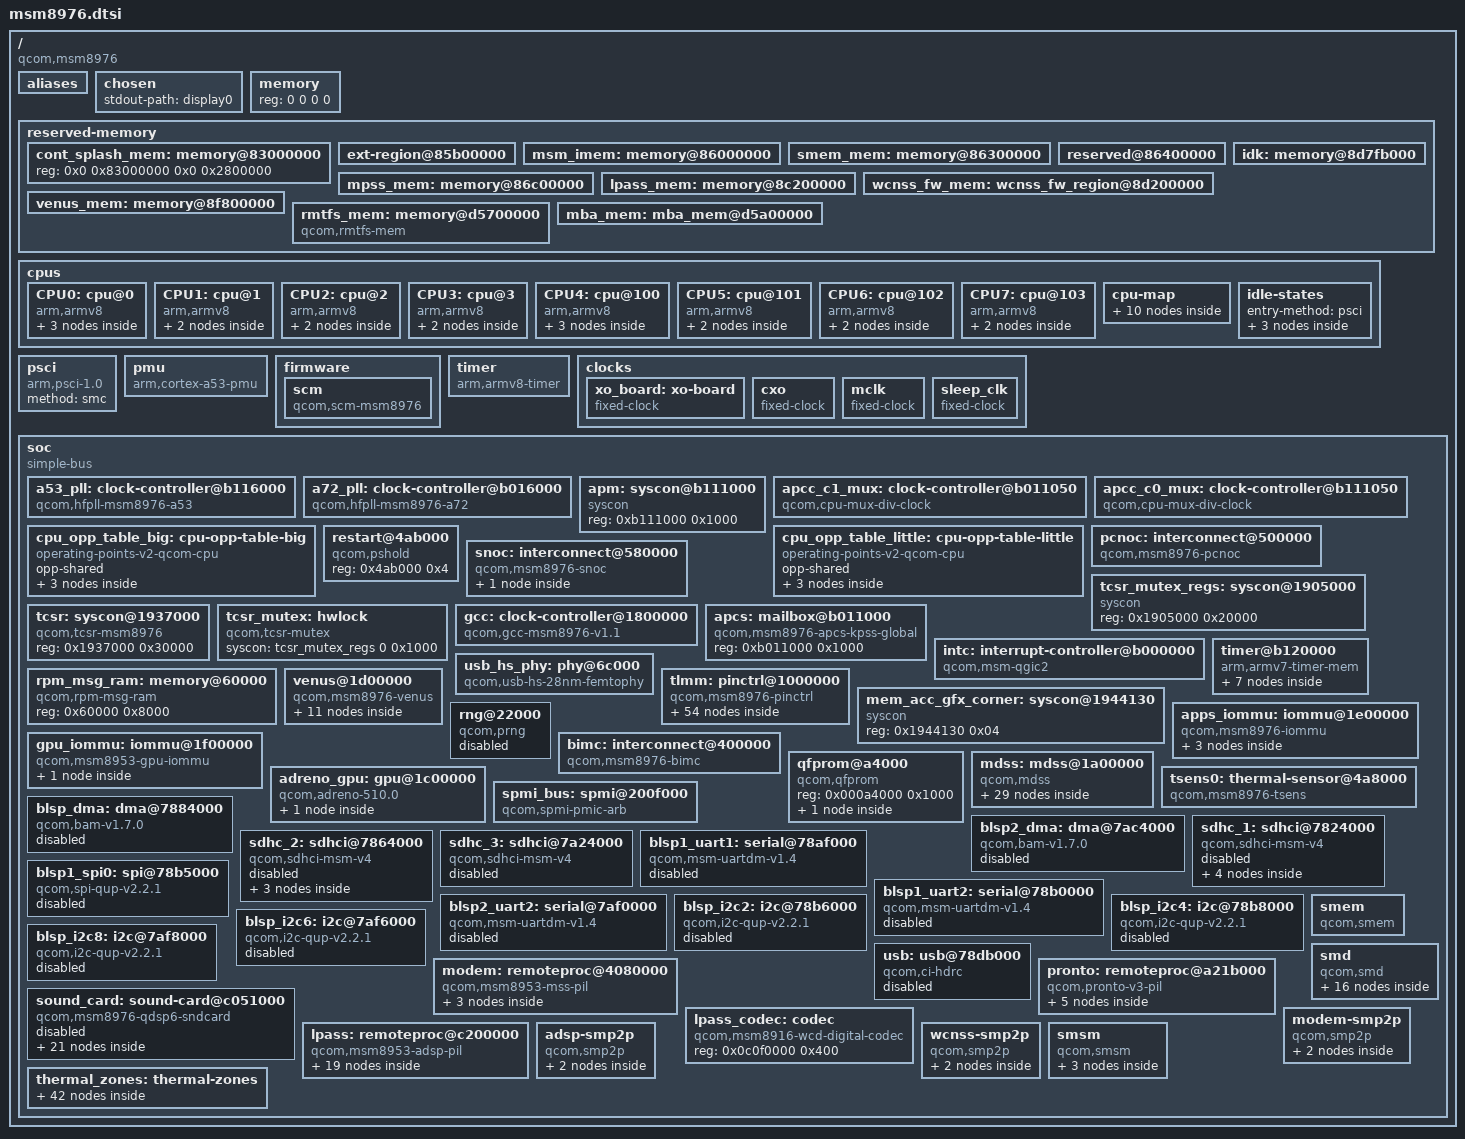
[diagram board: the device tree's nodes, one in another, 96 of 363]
// SPDX-License-Identifier: GPL-2.0
/* Copyright (c) 2014-2015, The Linux Foundation. All rights reserved.
 * Copyright (c) 2016-2019 AngeloGioacchino Del Regno <kholk11@gmail.com>
 */

#include <dt-bindings/interrupt-controller/arm-gic.h>
#include <dt-bindings/clock/qcom,gcc-msm8976.h>
#include <dt-bindings/interconnect/qcom,msm8976.h>
#include <dt-bindings/clock/qcom,rpmcc.h>
#include <dt-bindings/power/qcom-rpmpd.h>
#include <dt-bindings/soc/qcom,apr.h>
#include <dt-bindings/sound/qcom,q6afe.h>
#include <dt-bindings/sound/qcom,q6asm.h>
#include <dt-bindings/sound/qcom,q6voice.h>
#include <dt-bindings/thermal/thermal.h>


#define GPU_OPP(freq_khz, peakBW, lvl, supp)		\
	opp-##freq_khz##000 {				\
		opp-hz = /bits/ 64 <freq_khz##000>;	\
		opp-supported-hw = <supp>;		\
		opp-avg-kBps = <0>, <(peakBW/4)>;	\
		opp-peak-kBps = <peakBW>, <(peakBW/2)>;	\
		required-opps = <&lvl>;			\
	}

/ {
	interrupt-parent = <&intc>;
	#address-cells = <2>;
	#size-cells = <2>;

	compatible = "qcom,msm8976";
	qcom,msm-id = <278 0x10001>; /* MSM8976 */



	aliases {
		display0 = &mdss;
		mmc0 = &sdhc_1;
		mmc1 = &sdhc_2;
	};

	chosen {
		#address-cells = <2>;
		#size-cells = <2>;
		ranges;
		stdout-path = "display0";
		 };

	memory {
		device_type = "memory";
		/* We expect the bootloader to fill in the reg */
		reg = <0 0 0 0>;
	};

	reserved-memory {
		#address-cells = <2>;
		#size-cells = <2>;
		ranges;

		cont_splash_mem: memory@83000000 {
			reg = <0x0 0x83000000 0x0 0x2800000>;
		};

		ext-region@85b00000 {
			reg = <0x0 0x85b00000 0x0 0x500000>;
			no-map;
		};

		msm_imem: memory@86000000 {
			reg = <0x0 0x86000000 0x0 0x300000>;
			no-map;
		};

		smem_mem: memory@86300000 {
			reg = <0x0 0x86300000 0x0 0x100000>;
			no-map;
		};

		reserved@86400000 {
			reg = <0x0 0x86400000 0x0 0x800000>;
			no-map;
		};
	
		mpss_mem: memory@86c00000 {
			reg = <0x0 0x86c00000 0x0 0x5600000>;
			no-map;
		};

		lpass_mem: memory@8c200000 {
			reg = <0x0 0x8c200000 0x0 0x1000000>;
			no-map;
		};
		
		
		wcnss_fw_mem: wcnss_fw_region@8d200000 {
			no-map;
			reg = <0x0 0x8d200000  0x0 0x5FB000>;
		};
		
			idk: memory@8d7fb000 {
			reg = <0x0 0x8D7FB000 0x0 0x2005000>;
			no-map;
	 };
	 

		venus_mem: memory@8f800000 {
			reg = <0x0 0x8f800000 0x0 0x500000>;
			no-map;
		};
		
		rmtfs_mem: memory@d5700000 {
			compatible = "qcom,rmtfs-mem";
			reg = <0x0 0xd5700000 0x0 0x200000>;
			no-map;

			qcom,client-id = <1>;
		};
		
		mba_mem: mba_mem@d5a00000 {
			reg = <0x0 0xd5a00000 0x0 0x100000>;
			no-map;
		};
		
	};

	cpus {
		#address-cells = <1>;
		#size-cells = <0>;

		CPU0: cpu@0 {
			device_type = "cpu";
			compatible = "arm,armv8";
			reg = <0x0>;
			enable-method = "psci";
			cpu-idle-states = <&LITTLE_CPU_SLEEP_0>;
			capacity-dmips-mhz = <1024>;
			next-level-cache = <&L2_0>;
			clocks = <&apcc_c0_mux>;
			operating-points-v2 = <&cpu_opp_table_little>;
			#cooling-cells = <2>;
			L2_0: l2-cache {
				compatible = "arm,arch-cache";
				cache-level = <2>;
			};
			L1_I_0: l1-icache {
				compatible = "arm,arch-cache";
			};
			L1_D_0: l1-dcache {
				compatible = "arm,arch-cache";
			};
		};

		CPU1: cpu@1 {
			device_type = "cpu";
			compatible = "arm,armv8";
			reg = <0x1>;
			enable-method = "psci";
			cpu-idle-states = <&LITTLE_CPU_SLEEP_0>;
			capacity-dmips-mhz = <1024>;
			next-level-cache = <&L2_0>;
			clocks = <&apcc_c0_mux>;
			operating-points-v2 = <&cpu_opp_table_little>;
			#cooling-cells = <2>;
			L1_I_1: l1-icache {
				compatible = "arm,arch-cache";
			};
			L1_D_1: l1-dcache {
				compatible = "arm,arch-cache";
			};
		};

		CPU2: cpu@2 {
			device_type = "cpu";
			compatible = "arm,armv8";
			reg = <0x2>;
			enable-method = "psci";
			cpu-idle-states = <&LITTLE_CPU_SLEEP_0>;
			capacity-dmips-mhz = <1024>;
			next-level-cache = <&L2_0>;
			clocks = <&apcc_c0_mux>;
			operating-points-v2 = <&cpu_opp_table_little>;
			#cooling-cells = <2>;
			L1_I_2: l1-icache {
				compatible = "arm,arch-cache";
			};
			L1_D_2: l1-dcache {
				compatible = "arm,arch-cache";
			};
		};

		CPU3: cpu@3 {
			device_type = "cpu";
			compatible = "arm,armv8";
			reg = <0x3>;
			enable-method = "psci";
			cpu-idle-states = <&LITTLE_CPU_SLEEP_0>;
			capacity-dmips-mhz = <1024>;
			next-level-cache = <&L2_0>;
			clocks = <&apcc_c0_mux>;
			operating-points-v2 = <&cpu_opp_table_little>;
			#cooling-cells = <2>;
			L1_I_3: l1-icache {
				compatible = "arm,arch-cache";
			};
			L1_D_3: l1-dcache {
				compatible = "arm,arch-cache";
			};
		};

		CPU4: cpu@100 {
			device_type = "cpu";
			compatible = "arm,armv8";
			reg = <0x100>;
			enable-method = "psci";
			cpu-idle-states = <&BIG_CPU_SLEEP_0 &BIG_CPU_SLEEP_1>;
			capacity-dmips-mhz = <1830>;
			next-level-cache = <&L2_1>;
			clocks = <&apcc_c0_mux>;
			operating-points-v2 = <&cpu_opp_table_little>;
			#cooling-cells = <2>;
			L2_1: l2-cache {
				compatible = "arm,arch-cache";
				cache-level = <2>;
			};
			L1_I_100: l1-icache {
				compatible = "arm,arch-cache";
			};
			L1_D_100: l1-dcache {
				compatible = "arm,arch-cache";
			};
		};

		CPU5: cpu@101 {
			device_type = "cpu";
			compatible = "arm,armv8";
			reg = <0x101>;
			enable-method = "psci";
			cpu-idle-states = <&BIG_CPU_SLEEP_0 &BIG_CPU_SLEEP_1>;
			capacity-dmips-mhz = <1830>;
			next-level-cache = <&L2_1>;
			clocks = <&apcc_c1_mux>;
			operating-points-v2 = <&cpu_opp_table_big>;
			#cooling-cells = <2>;
			L1_I_101: l1-icache {
				compatible = "arm,arch-cache";
			};
			L1_D_101: l1-dcache {
				compatible = "arm,arch-cache";
			};
		};

		CPU6: cpu@102 {
			device_type = "cpu";
			compatible = "arm,armv8";
			reg = <0x102>;
			enable-method = "psci";
			cpu-idle-states = <&BIG_CPU_SLEEP_0 &BIG_CPU_SLEEP_1>;
			capacity-dmips-mhz = <1830>;
			next-level-cache = <&L2_1>;
			clocks = <&apcc_c1_mux>;
			operating-points-v2 = <&cpu_opp_table_big>;
			#cooling-cells = <2>;
			L1_I_102: l1-icache {
				compatible = "arm,arch-cache";
			};
			L1_D_102: l1-dcache {
				compatible = "arm,arch-cache";
			};
		};

		CPU7: cpu@103 {
			device_type = "cpu";
			compatible = "arm,armv8";
			reg = <0x103>;
			enable-method = "psci";
			cpu-idle-states = <&BIG_CPU_SLEEP_0 &BIG_CPU_SLEEP_1>;
			capacity-dmips-mhz = <1830>;
			next-level-cache = <&L2_1>;
			clocks = <&apcc_c1_mux>;
			operating-points-v2 = <&cpu_opp_table_big>;
			#cooling-cells = <2>;
			L1_I_103: l1-icache {
				compatible = "arm,arch-cache";
			};
			L1_D_103: l1-dcache {
				compatible = "arm,arch-cache";
			};
		};

		cpu-map {
			cluster0 {
				core0 {
					cpu = <&CPU0>;
				};

				core1 {
					cpu = <&CPU1>;
				};

				core2 {
					cpu = <&CPU2>;
				};

				core3 {
					cpu = <&CPU3>;
				};
			};

			cluster1 {
				core0 {
					cpu = <&CPU4>;
				};

				core1 {
					cpu = <&CPU5>;
				};

				core2 {
					cpu = <&CPU6>;
				};

				core3 {
					cpu = <&CPU7>;
				};
			};
		};

		idle-states {
			entry-method = "psci";

			LITTLE_CPU_SLEEP_0: cpu-sleep-0-0 {
				compatible = "arm,idle-state";
				idle-state-name = "little-power-collapse";
				arm,psci-suspend-param = <0x40000003>;
				entry-latency-us = <181>;
				exit-latency-us = <149>;
				min-residency-us = <703>;
				local-timer-stop;
			};

			BIG_CPU_SLEEP_0: cpu-sleep-1-0 {
				compatible = "arm,idle-state";
				idle-state-name = "big-retention";
				arm,psci-suspend-param = <0x00000002>;
				entry-latency-us = <142>;
				exit-latency-us = <99>;
				min-residency-us = <242>;
			};

			BIG_CPU_SLEEP_1: cpu-sleep-1-1 {
				compatible = "arm,idle-state";
				idle-state-name = "big-power-collapse";
				arm,psci-suspend-param = <0x40000003>;
				entry-latency-us = <158>;
				exit-latency-us = <144>;
				min-residency-us = <863>;
				local-timer-stop;
			};
		};
	};

	psci {
		compatible = "arm,psci-1.0";
		method = "smc";
	};

	pmu {
		compatible = "arm,cortex-a53-pmu";
		interrupts = <GIC_PPI 7 (GIC_CPU_MASK_SIMPLE(8)| IRQ_TYPE_LEVEL_HIGH)>;
	};
	
	firmware {
		scm: scm {
			compatible = "qcom,scm-msm8976", "qcom,scm";
			clocks = <&gcc GCC_CRYPTO_CLK>,
				 <&gcc GCC_CRYPTO_AXI_CLK>,
				 <&gcc GCC_CRYPTO_AHB_CLK>;
			clock-names = "core", "bus", "iface";
			#reset-cells = <1>;

			//qcom,dload-mode = <&tcsr 0x6100>;
		};
	};
	
	timer {
		compatible = "arm,armv8-timer";
		interrupts = <GIC_PPI 2 (GIC_CPU_MASK_SIMPLE(1) | IRQ_TYPE_LEVEL_LOW)>,
			     <GIC_PPI 3 (GIC_CPU_MASK_SIMPLE(1) | IRQ_TYPE_LEVEL_LOW)>,
			     <GIC_PPI 4 (GIC_CPU_MASK_SIMPLE(1) | IRQ_TYPE_LEVEL_LOW)>,
			     <GIC_PPI 1 (GIC_CPU_MASK_SIMPLE(1) | IRQ_TYPE_LEVEL_LOW)>;
		clock-frequency = <19200000>;
	};

	clocks {
		xo_board: xo-board {
			compatible = "fixed-clock";
			#clock-cells = <0>;
			clock-frequency = <19200000>;
			clock-output-names = "xo";
		};
		
		cxo: cxo {
			compatible = "fixed-clock";
			#clock-cells = <0>;
			clock-frequency = <19200000>;
			clock-output-names = "cxo";
		};
		
		mclk: mclk {
			compatible = "fixed-clock";
			#clock-cells = <0>;
			clock-frequency = <9600000>;
			clock-output-names = "mclk";
		};

		sleep_clk: sleep_clk {
			compatible = "fixed-clock";
			#clock-cells = <0>;
			clock-frequency = <32764>;
			clock-output-names = "sleep_clk";
		};
	};

	soc: soc {
		#address-cells = <1>;
		#size-cells = <1>;
		ranges = <0 0 0 0xffffffff>;
		compatible = "simple-bus";
		
	a53_pll: clock-controller@b116000 {
		compatible = "qcom,hfpll-msm8976-a53", "qcom,hfpll2";
		reg = <0xb116000 0x40>;
		clocks = <&xo_board>;
		clock-names = "xo";
		clock-output-names = "hfpll_a53";
		#clock-cells = <0>;
	};

	a72_pll: clock-controller@b016000 {
		compatible = "qcom,hfpll-msm8976-a72", "qcom,hfpll2";
		reg = <0xb016000 0x40>;
		clocks = <&xo_board>;
		clock-names = "xo";
		clock-output-names = "hfpll_a72";
		#clock-cells = <0>;
	};
	
	apm: syscon@b111000 {
			compatible = "syscon";
			reg = <0xb111000 0x1000>;
		};
	
	apcc_c1_mux: clock-controller@b011050 {
			compatible = "qcom,cpu-mux-div-clock";
			reg = <0xb011050 0x10>;
			clocks = <&a72_pll>, <&gcc GPLL0>;
			qcom,mux-values = <5>, <4>; //5 is main pll output 4 is aux clock=gpll0
			qcom,safe-div = <3>;
			clock-output-names = "apcc-c1-mux";
			assigned-clocks = <&apcc_c1_mux>;
			assigned-clock-parents = <&a72_pll>;
			assigned-clock-rates = <1804800000>;
			#clock-cells = <0>;
		};
		
		apcc_c0_mux: clock-controller@b111050 {
			compatible = "qcom,cpu-mux-div-clock";
			reg = <0xb111050 0x10>;
			clocks = <&a53_pll>, <&gcc GPLL0>;
			qcom,mux-values = <5>, <4>;
			qcom,safe-div = <3>;
			clock-output-names = "apcc-c0-mux";
			assigned-clocks = <&apcc_c0_mux>;
			assigned-clock-parents = <&a53_pll>;
			assigned-clock-rates = <1401600000>;
			#clock-cells = <0>;
		};
		
		cpu_opp_table_big: cpu-opp-table-big {
		compatible = "operating-points-v2-qcom-cpu";
		opp-shared;

		opp-400000000 {
			opp-hz = /bits/ 64 <400000000>;
		};

		opp-883200000 {
			opp-hz = /bits/ 64 <883200000>;
		};
		opp-1056000000 {
			opp-hz = /bits/ 64 <1056000000>;
		};
		/*
		
		opp-1382400000 {
			opp-hz = /bits/ 64 <1382400000>;
		};
		
		opp-1804800000 {
		 	opp-hz = /bits/ 64 <1804800000>;
		};
		*/
	};

	cpu_opp_table_little: cpu-opp-table-little {
		compatible = "operating-points-v2-qcom-cpu";
		opp-shared;

		opp-400000000 {
			opp-hz = /bits/ 64 <400000000>;
		};

		opp-806400000 {
			opp-hz = /bits/ 64 <806400000>;
		};
		opp-1190400000 {
			opp-hz = /bits/ 64 <1190400000>;
		};
		/*
		opp-1382400000 {
			opp-hz = /bits/ 64 <1382400000>;
		};
		
		opp-1440000000 {
		 	opp-hz = /bits/ 64 <1440000000>;
		};
		*/
	};

/*
		apcc_cci_mux: clock-controller@b1d1050 {
			compatible = "qcom,cpu-mux-div-clock";
			reg = <0xb1d1050 0x10>;
			clocks = <&apcc_pll>, <&gcc GPLL0>;
			qcom,mux-values = <5>, <4>;
			qcom,safe-div = <4>;
			clock-output-names = "apcc-cci-mux";
			assigned-clocks = <&apcc_cci_mux>;
			assigned-clock-parents = <&apcc_pll>;
			assigned-clock-rates = <614400000>;
			#clock-cells = <0>;
		};
	*/
		
		restart@4ab000 {
			compatible = "qcom,pshold";
			reg = <0x4ab000 0x4>;
		};
		
		pcnoc: interconnect@500000 {
			compatible = "qcom,msm8976-pcnoc";
			reg = <0x500000 0x14000>;

			clock-names = "bus", "bus_a";
			clocks = <&rpmcc RPM_SMD_PCNOC_CLK>,
				 <&rpmcc RPM_SMD_PCNOC_A_CLK>;

			#interconnect-cells = <1>;
		};

		snoc: interconnect@580000 {
			compatible = "qcom,msm8976-snoc";
			reg = <0x580000 0x1a000>;

			clock-names = "bus", "bus_a";
			clocks = <&rpmcc RPM_SMD_SNOC_CLK>,
				 <&rpmcc RPM_SMD_SNOC_A_CLK>;

			#interconnect-cells = <1>;

			snoc_mm: interconnect {
				compatible = "qcom,msm8976-snoc-mm";

				clock-names = "bus", "bus_a";
				clocks = <&rpmcc RPM_SMD_SYSMMNOC_CLK>,
					 <&rpmcc RPM_SMD_SYSMMNOC_A_CLK>;

				#interconnect-cells = <1>;
			};
		};


		tcsr_mutex_regs: syscon@1905000 {
			compatible = "syscon";
			reg = <0x1905000 0x20000>;
		};

		tcsr: syscon@1937000 {
			compatible = "qcom,tcsr-msm8976", "syscon";
			reg = <0x1937000 0x30000>;
		};
		
		tcsr_mutex: hwlock {
			compatible = "qcom,tcsr-mutex";
			syscon = <&tcsr_mutex_regs 0 0x1000>;
			#hwlock-cells = <1>;
		};
	
		gcc: clock-controller@1800000 {
			compatible ="qcom,gcc-msm8976-v1.1";
			#clock-cells = <1>;
			#reset-cells = <1>;
			#power-domain-cells = <1>;
			reg = <0x1800000 0x80000>;
			 clocks = <&xo_board>,
          			     <&xo_board>,
           			    <&dsi0_phy 1>,
           			    <&dsi0_phy 0>,
           			    <&dsi1_phy 1>,
         		  	    <&dsi1_phy 0>;

    			  clock-names = "xo",
              		 	        "xo_a",
                    			"dsi0pll",
                    			"dsi0pllbyte",
                    			"dsi1pll",
                   			"dsi1pllbyte";
		};

		apcs: mailbox@b011000 {
			compatible = "qcom,msm8976-apcs-kpss-global", "syscon";
			reg = <0xb011000 0x1000>;
			#mbox-cells = <1>;
		};
		
		intc: interrupt-controller@b000000 {
			compatible = "qcom,msm-qgic2";
			interrupt-controller;
			#interrupt-cells = <3>;
			reg = <0x0b000000 0x1000>,
			      <0x0b002000 0x1000>;
		};
		
		rpm_msg_ram: memory@60000 {
			compatible = "qcom,rpm-msg-ram";
			reg = <0x60000 0x8000>;
		};
		
		timer@b120000 {
			#address-cells = <1>;
			#size-cells = <1>;
			ranges;
			compatible = "arm,armv7-timer-mem";
			reg = <0x0b120000 0x1000>;
			clock-frequency = <19200000>;

			frame@b121000 {
				frame-number = <0>;
				interrupts = <GIC_SPI 8 IRQ_TYPE_LEVEL_HIGH>,
					     <GIC_SPI 7 IRQ_TYPE_LEVEL_HIGH>;
				reg = <0x0b121000 0x1000>,
				      <0x0b122000 0x1000>;
			};

			frame@b123000 {
				frame-number = <1>;
				interrupts = <GIC_SPI 9 IRQ_TYPE_LEVEL_HIGH>;
				reg = <0x0b123000 0x1000>;
				status = "disabled";
			};

			frame@b124000 {
				frame-number = <2>;
				interrupts = <GIC_SPI 10 IRQ_TYPE_LEVEL_HIGH>;
				reg = <0x0b124000 0x1000>;
				status = "disabled";
			};

			frame@b125000 {
				frame-number = <3>;
				interrupts = <GIC_SPI 11 IRQ_TYPE_LEVEL_HIGH>;
				reg = <0x0b125000 0x1000>;
				status = "disabled";
			};

			frame@b126000 {
				frame-number = <4>;
				interrupts = <GIC_SPI 12 IRQ_TYPE_LEVEL_HIGH>;
				reg = <0x0b126000 0x1000>;
				status = "disabled";
			};

			frame@b127000 {
				frame-number = <5>;
				interrupts = <GIC_SPI 13 IRQ_TYPE_LEVEL_HIGH>;
				reg = <0x0b127000 0x1000>;
				status = "disabled";
			};

			frame@b128000 {
				frame-number = <6>;
				interrupts = <GIC_SPI 14 IRQ_TYPE_LEVEL_HIGH>;
				reg = <0x0b128000 0x1000>;
				status = "disabled";
			};
		};
		
			
		usb_hs_phy: phy@6c000 {
			compatible = "qcom,usb-hs-28nm-femtophy";
			reg = <0x0006c000 0x200>;
			#phy-cells = <0>;
			clocks = <&xo_board>,
				 <&gcc GCC_USB_HS_PHY_CFG_AHB_CLK>,
				 <&gcc GCC_USB2A_PHY_SLEEP_CLK>; 
			clock-names = "ref", "ahb", "sleep";
			resets = <&gcc RST_QUSB2_PHY_BCR>,
			<&gcc RST_USB2_HS_PHY_ONLY_BCR>;
			reset-names = "phy", "por";
		};
		
		tlmm: pinctrl@1000000 {
			compatible = "qcom,msm8976-pinctrl";
			reg = <0x01000000 0x300000>;
			interrupts = <GIC_SPI 208 IRQ_TYPE_LEVEL_HIGH>;
			gpio-controller;
			#gpio-cells = <2>;
			interrupt-controller;
			#interrupt-cells = <2>;

			blsp1_uart1_default: blsp1_uart1_default {
				pins = "gpio0", "gpio1", "gpio2", "gpio3";
				function = "blsp_uart1";

				drive-strength = <16>;
				bias-disable;
			};

			blsp1_uart2_default: blsp1_uart2_default {
				pins = "gpio4", "gpio5", "gpio6", "gpio7";
				function = "blsp_uart2";

				drive-strength = <2>;
				bias-disable;
			};

			blsp2_uart2_default: blsp2_uart2_default {
				pins = "gpio20", "gpio21";
				function = "blsp_uart6";

				drive-strength = <2>;
				bias-disable;
			};

			spi0_default: spi0_default {
				bus {
					/* MOSI, MISO, CLK */
					pins = "gpio0", "gpio1", "gpio3";
					function = "blsp_spi1";

					drive-strength = <12>;
				};

				cs0 {
					pins = "gpio2";
					function = "blsp_spi1";

					drive-strength = <2>;
				};
			};

			i2c2_default: i2c2_default {
				pins = "gpio6", "gpio7";
				function = "blsp_i2c2";
				bias-disable;
				drive-strength = <2>;
			};

			i2c_2_sleep: i2c-2-sleep-pins {
				pins = "gpio6", "gpio7";
				function = "gpio";
				drive-strength = <2>;
				bias-disable;
			};

			i2c4_default: i2c4_default {
				pins = "gpio14", "gpio15";
				function = "blsp_i2c4";
				bias-disable;
				drive-strength = <2>;
			};

			i2c4_sleep: i2c4_sleep{
				pins = "gpio14", "gpio15";
				function = "blsp_i2c4";
				bias-disable;
				drive-strength = <2>;
			};

			i2c6_default: i2c6_default {
				pins = "gpio22", "gpio23";
				function = "blsp_i2c6";
				bias-disable;
				drive-strength = <2>;
			};

			i2c6_sleep: i2c6_sleep {
				pins = "gpio22", "gpio23";
				function = "blsp_i2c6";
				bias-disable;
				drive-strength = <2>;
			};

			i2c8_default: i2c8_default {
				pins = "gpio18", "gpio19";
				function = "blsp_i2c8";
				bias-disable;
				drive-strength = <2>;
			};

			i2c8_sleep: i2c8_sleep{
				pins = "gpio18", "gpio19";
				function = "blsp_i2c8";
				bias-disable;
				drive-strength = <2>;
			};

			cci0_i2c_default: cci0_i2c_default {
				pins = "gpio29", "gpio30";
				function = "cci0_i2c";

				drive-strength = <2>;
				bias-disable;
			};

			cci1_i2c_default: cci1_i2c_default {
				pins = "gpio103", "gpio104";
				function = "cci0_i2c";

				drive-strength = <2>;
				bias-disable;
			};

			camss_mclk0_default: camss-mclk0-pins {
				pins = "gpio26";
				function = "cam_mclk";
				drive-strength = <2>;
				bias-disable;
			};

			camss_mclk1_default: camss-mclk1-pins {
				pins = "gpio28";
				function = "cam_mclk";
				drive-strength = <2>;
				bias-disable;
			};

			mdss_te_default: mdss-te-pins {
				pins = "gpio24";
				function = "mdp_vsync";
				drive-strength = <2>;
				bias-pull-down;
			};

			/* SDC pin type */
			sdc1_clk_on: sdc1-clk-on-pins {
				pins = "sdc1_clk";
				bias-disable;
				drive-strength = <16>;
			};

			sdc1_clk_off: sdc1-clk-off-pins {
				pins = "sdc1_clk";
				bias-disable;
				drive-strength = <2>;
			};

			sdc1_cmd_on: sdc1-cmd-on-pins {
				pins = "sdc1_cmd";
				bias-pull-up;
				drive-strength = <10>;
			};

			sdc1_cmd_off: sdc1-cmd-off-pins {
				pins = "sdc1_cmd";
				bias-pull-up;
				drive-strength = <2>;
			};

			sdc1_data_on: sdc1-data-on-pins {
				pins = "sdc1_data";
				bias-pull-up;
				drive-strength = <10>;
			};

			sdc1_data_off: sdc1-data-off-pins {
				pins = "sdc1_data";
				bias-pull-up;
				drive-strength = <2>;
			};

			sdc1_rclk_on: sdc1-rclk-on-pins {
				pins = "sdc1_rclk";
				bias-pull-down;
			};

			sdc1_rclk_off: sdc1-rclk-off-pins {
				pins = "sdc1_rclk";
				bias-pull-down;
			};

			sdc2_clk_on: sdc2-clk-on-pins {
				pins = "sdc2_clk";
				drive-strength = <16>;
				bias-disable;
			};

			sdc2_clk_off: sdc2-clk-off-pins {
				pins = "sdc2_clk";
				bias-disable;
				drive-strength = <2>;
			};

			sdc2_cmd_on: sdc2-cmd-on-pins {
				pins = "sdc2_cmd";
				bias-pull-up;
				drive-strength = <10>;
			};

			sdc2_cmd_off: sdc2-cmd-off-pins {
				pins = "sdc2_cmd";
				bias-pull-up;
				drive-strength = <2>;
			};

			sdc2_data_on: sdc2-data-on-pins {
				pins = "sdc2_data";
				bias-pull-up;
				drive-strength = <10>;
			};

			sdc2_data_off: sdc2-data-off-pins {
				pins = "sdc2_data";
				bias-pull-up;
				drive-strength = <2>;
			};

			sdc2_cd_on: cd-on-pins {
				pins = "gpio100";
				function = "gpio";
				drive-strength = <2>;
				bias-pull-up;
			};

			sdc2_cd_off: cd-off-pins {
				pins = "gpio100";
				function = "gpio";
				drive-strength = <2>;
				bias-disable;
			};

			gpio_key_default: gpio-key-default-pins {
				pins = "gpio113";
				function = "gpio";
				drive-strength = <2>;
				bias-pull-up;
			};

			/* Active configuration of bus pins */
			wcnss_default: wcnss-default-pins {
				wcss_wlan2 {
					pins = "gpio40";
					function = "wcss_wlan2";
				};
				wcss_wlan1 {
					pins = "gpio41";
					function = "wcss_wlan1";
				};
				wcss_wlan0 {
					pins = "gpio42";
					function = "wcss_wlan0";
				};
				wcss_wlan {
					pins = "gpio43", "gpio44";
					function = "wcss_wlan";
				};

				pinconf {
					pins = "gpio40", "gpio41",
						"gpio42", "gpio43",
						"gpio44";
					drive-strength = <6>;
					bias-pull-up;
				};
			};

			wcnss_sleep: wcnss-sleep-pins {
				wcss_wlan2 {
					pins = "gpio40";
					function = "wcss_wlan2";
				};
				wcss_wlan1 {
					pins = "gpio41";
					function = "wcss_wlan1";
				};
				wcss_wlan0 {
					pins = "gpio42";
					function = "wcss_wlan0";
				};
				wcss_wlan {
					pins = "gpio43", "gpio44";
					function = "wcss_wlan";
				};

				pinconf {
					pins = "gpio40", "gpio41",
						"gpio42", "gpio43",
						"gpio44";
					drive-strength = <2>;
					bias-pull-down;
				};
			};

			cdc_pdm_lines_2_act: pdm-lines-2-on-pins {
					pins = "gpio116", "gpio117", "gpio118", "gpio119";
					function = "cdc_pdm0";
					drive-strength = <8>;
			};

			cdc_pdm_lines_2_sus: pdm-lines-2-off-pins {
					pins = "gpio116", "gpio117", "gpio118", "gpio119";
					function = "cdc_pdm0";
					drive-strength = <2>;
					bias-disable;
			};

			cdc_pdm_lines_act: pdm-lines-on-pins {
					pins = "gpio120", "gpio121";
					function = "cdc_pdm0";
					drive-strength = <8>;
			};
			cdc_pdm_lines_sus: pdm-lines-off-pins {
					pins = "gpio120", "gpio121";
					function = "cdc_pdm0";
					drive-strength = <2>;
					bias-disable;
			};
			cdc_reset_active: cdc_reset_active {
					pins = "gpio133";
					function = "gpio";
					output-high;
					drive-strength = <16>;
					bias-disable;
			};
			cdc_reset_sus: cdc_reset_sus {
					pins = "gpio133";
					function = "gpio";
					output-low;
					drive-strength = <16>;
					bias-disable;
			};
		};


		mem_acc_gfx_corner: syscon@1944130 {
			compatible = "syscon";
			reg = <0x1944130 0x04>;
		};
		
		venus@1d00000 {
			compatible = "qcom,msm8976-venus";
			reg = <0x1d00000 0xff000>;

			interrupts = <GIC_SPI 44 IRQ_TYPE_LEVEL_HIGH>;

			clocks = <&gcc GCC_VENUS0_VCODEC0_CLK>,
				 <&gcc GCC_VENUS0_AHB_CLK>,
				 <&gcc GCC_VENUS0_AXI_CLK>,
				 <&gcc GCC_VENUS0_CORE0_VCODEC0_CLK>;
			clock-names = "core", "iface", "bus", "vcodec0";

			operating-points-v2 = <&venus_opp_table>;

			power-domains = <&gcc VENUS_GDSC>,
					<&rpmpd MSM8976_VDDCX>;
			power-domain-names = "venus", "cx";

			interconnects = <&snoc_mm MAS_VENUS_0 &bimc SLV_EBI>,
					<&bimc MAS_APPS_PROC &pcnoc SLV_VENUS_CFG>;
			interconnect-names = "video-mem", "cpu-cfg";

			iommus = <&apps_iommu 0x16>;

			memory-region = <&venus_mem>;

			video-decoder {
				compatible = "venus-decoder";
				power-domains = <&gcc VENUS_CORE0_GDSC>;
			};

			video-encoder {
				compatible = "venus-encoder";
				power-domains = <&gcc VENUS_CORE0_GDSC>;
			};

			venus_opp_table: venus-opp-table {
				compatible = "operating-points-v2";

				opp-100000000 {
					opp-hz = /bits/ 64 <100000000>;
					required-opps = <&rpmpd_opp_svs>;
				};
				
				opp-114290000 {
					opp-hz = /bits/ 64 <114290000>;
					required-opps = <&rpmpd_opp_svs>;
				};
				
				opp-133333333 {
					opp-hz = /bits/ 64 <133333333>;
					required-opps = <&rpmpd_opp_svs>;
				};

				opp-228570000 {
					opp-hz = /bits/ 64 <228570000>;
					required-opps = <&rpmpd_opp_svs>;
				};

				opp-310667000 {
					opp-hz = /bits/ 64 <310667000>;
					required-opps = <&rpmpd_opp_svs_plus>;
				};

				opp-360000000 {
					opp-hz = /bits/ 64 <360000000>;
					required-opps = <&rpmpd_opp_nom>;
				};

				opp-400000000 {
					opp-hz = /bits/ 64 <400000000>;
					required-opps = <&rpmpd_opp_nom_plus>;
				};

				opp-466000000 {
					opp-hz = /bits/ 64 <466000000>;
					required-opps = <&rpmpd_opp_turbo>;
				};

			};
		};
		
	apps_iommu: iommu@1e00000 {
			#address-cells = <1>;
			#size-cells = <1>;
			#iommu-cells = <1>;
			#global-interrupts = <0>;
			compatible = "qcom,msm8976-iommu", "qcom,msm-iommu-v1";
			ranges  = <0 0x1e20000 0x20000>;
			clocks = <&gcc GCC_SMMU_CFG_CLK>,
				 <&gcc GCC_APSS_TCU_CLK>;
			clock-names = "iface", "bus";
			qcom,iommu-secure-id = <17>;
			status = "ok";

			iommu-ctx@15000 { // vfe
				compatible = "qcom,msm-iommu-v1-sec";
				reg = <0x15000 0x1000>;
				interrupts = <GIC_SPI 113 IRQ_TYPE_LEVEL_HIGH>;
			};
			
			iommu-ctx@16000 { // venus_ns
				compatible = "qcom,msm-iommu-v1-sec";
				reg = <0x16000 0x1000>;
				interrupts = <GIC_SPI 114 IRQ_TYPE_LEVEL_HIGH>;
			};
			
			iommu-ctx@17000 { // mdp_0
				compatible = "qcom,msm-iommu-v1-ns";
				reg = <0x17000 0x1000>;
				interrupts = <GIC_SPI 115 IRQ_TYPE_LEVEL_HIGH>;
			};



		};

		gpu_iommu: iommu@1f00000 {
			#address-cells = <1>;
			#size-cells = <1>;
			#iommu-cells = <1>;
			compatible = "qcom,msm8953-gpu-iommu", "qcom,msm-iommu-v1";
			ranges = <0 0x01f08000 0x8000>;
			clocks = <&gcc GCC_SMMU_CFG_CLK>,
				 <&gcc GCC_GFX3D_TCU_CLK>;
			clock-names = "iface", "bus";
			qcom,iommu-secure-id = <18>;
			power-domains = <&gcc OXILI_CX_GDSC>;

		// gfx3d_user:
			iommu-ctx@0000 {
				compatible = "qcom,msm-iommu-v1-ns";
				reg = <0x0 0x1000>;
				interrupts = <GIC_SPI 240 IRQ_TYPE_LEVEL_HIGH>;
			};

		};

		rng@22000 {
			status = "disabled";
			compatible = "qcom,prng";
			reg = <0x00022000 0x140>;
			clocks = <&gcc GCC_PRNG_AHB_CLK>;
			clock-names = "core";
		};
		
		bimc: interconnect@400000 {
			compatible = "qcom,msm8976-bimc";
			reg = <0x400000 0x62000>;

			clock-names = "bus", "bus_a";
			clocks = <&rpmcc RPM_SMD_BIMC_CLK>,
				 <&rpmcc RPM_SMD_BIMC_A_CLK>;

			#interconnect-cells = <1>;
		};

		qfprom@a4000 {
			compatible = "qcom,qfprom";
			reg = <0x000a4000 0x1000>;
			#address-cells = <1>;
			#size-cells = <1>;

			tsens_caldata: caldata@218 {
				reg = <0x218 0x18>;
			};
		};

		mdss: mdss@1a00000 {
			compatible = "qcom,mdss";
			reg = <0x01a00000 0x1000>,
			      <0x01ac8000 0x3000>;
			reg-names = "mdss_phys", "vbif_phys";

			power-domains = <&gcc MDSS_GDSC>;
			interrupts = <GIC_SPI 72 IRQ_TYPE_LEVEL_HIGH>;

			interrupt-controller;
			#interrupt-cells = <1>;

			clocks = <&gcc GCC_MDSS_AHB_CLK>,
				 <&gcc GCC_MDSS_AXI_CLK>,
				 <&gcc GCC_MDSS_VSYNC_CLK>;
			clock-names = "iface",
				      "bus",
				      "vsync";

			#address-cells = <1>;
			#size-cells = <1>;
			ranges;

			mdp: mdp@1a01000 {
				compatible = "qcom,mdp5";
				reg = <0x01a01000 0x89000>;
				reg-names = "mdp_phys";

				interrupt-parent = <&mdss>;
				interrupts = <0 IRQ_TYPE_LEVEL_HIGH>;

				clocks = <&gcc GCC_MDSS_AHB_CLK>,
					 <&gcc GCC_MDSS_AXI_CLK>,
					 <&gcc GCC_MDSS_MDP_CLK>,
					 <&gcc GCC_MDSS_VSYNC_CLK>,
					 <&gcc GCC_MDP_TBU_CLK>,
					 <&gcc GCC_MDP_RT_TBU_CLK>;
				clock-names = "iface",
					      "bus",
					      "core",
					      "vsync",
					      "tbu",
					      "tbu_rt";
				
				interconnects = <&snoc_mm MAS_MDP0 &bimc SLV_EBI>,
						<&snoc_mm MAS_MDP1 &bimc SLV_EBI>,
						<&bimc MAS_APPS_PROC &pcnoc SLV_DISP_SS_CFG>;
				interconnect-names = "mdp0-mem"," mdp1-mem", "rotator-mem";
				operating-points-v2 = <&mdp_opp_table>;
				power-domains = <&rpmpd MSM8976_VDDCX>;
				
				iommus = <&apps_iommu 0x17>;
				iommu-defer-attach;

				ports {
					#address-cells = <1>;
					#size-cells = <0>;

					port@0 {
						reg = <0>;
						mdp5_intf1_out: endpoint {
							remote-endpoint = <&dsi0_in>;
						};
					};

					port@1 {
						reg = <1>;
						mdp5_intf2_out: endpoint {
							remote-endpoint = <&dsi1_in>;
						};
					};
				};
				
				mdp_opp_table: mdp-opp {
					compatible = "operating-points-v2";

					opp-177780000 {
						opp-hz = /bits/ 64 <177780000>;
						opp-peak-kBps = <320000 320000 76800>;
						required-opps = <&rpmpd_opp_svs>; //LOWER
					};
					opp-270000000 {
						opp-hz = /bits/ 64 <270000000>;
						opp-peak-kBps = <6400000 6400000 76800>;
						required-opps = <&rpmpd_opp_svs_plus>; //LOW
					};
				
					opp-320000000 {
						opp-hz = /bits/ 64 <320000000>;
						opp-peak-kBps = <6400000 6400000 76800>;
						required-opps = <&rpmpd_opp_nom>;
					};
					opp-360000000 {
						opp-hz = /bits/ 64 <360000000>;
						opp-peak-kBps = <6400000 6400000 76800>;
						required-opps = <&rpmpd_opp_turbo>;
					};
				};
			};

			dsi0: dsi@1a94000 {
				compatible = "qcom,mdss-dsi-ctrl";
				reg = <0x01a94000 0x25c>;
				reg-names = "dsi_ctrl";

				interrupt-parent = <&mdss>;
				interrupts = <4 IRQ_TYPE_LEVEL_HIGH>;

				assigned-clocks =
					<&gcc GCC_MDSS_BYTE0_CLK_SRC>,
					<&gcc GCC_MDSS_PCLK0_CLK_SRC>;
				assigned-clock-parents = <&dsi0_phy 0>,
							 <&dsi0_phy 1>;

				clocks = <&gcc GCC_MDSS_MDP_CLK>,
					 <&gcc GCC_MDSS_AHB_CLK>,
					 <&gcc GCC_MDSS_AXI_CLK>,
					 <&gcc GCC_MDSS_BYTE0_CLK>,
					 <&gcc GCC_MDSS_PCLK0_CLK>,
					 <&gcc GCC_MDSS_ESC0_CLK>;
				clock-names = "mdp_core",
					      "iface",
					      "bus",
					      "byte",
					      "pixel",
					      "core";

				phys = <&dsi0_phy>;
				phy-names = "dsi-phy";
				operating-points-v2 = <&dsi0_opp_table>;
				power-domains = <&rpmpd MSM8976_VDDCX>;

				#address-cells = <1>;
				#size-cells = <0>;

			
				ports {
					#address-cells = <1>;
					#size-cells = <0>;

					port@0 {
						reg = <0>;
						dsi0_in: endpoint {
							remote-endpoint = <&mdp5_intf1_out>;
						};
					};

					port@1 {
						reg = <1>;
						dsi0_out: endpoint {
						};
					};
				};
				
				dsi0_opp_table: dsi-opp-table {
					compatible = "operating-points-v2";

					opp-125000000 {
						opp-hz = /bits/ 64 <125000000>;
						required-opps = <&rpmpd_opp_svs>;

					};

					opp-161250000 {
						opp-hz = /bits/ 64 <161250000>;
						required-opps = <&rpmpd_opp_svs_plus>;
					};

					opp-187500000 {
						opp-hz = /bits/ 64 <187500000>;
						required-opps = <&rpmpd_opp_nom>;
					};
				};
			};

			dsi1: dsi@1a96000 {
				compatible = "qcom,mdss-dsi-ctrl";
				reg = <0x01a96000 0x300>;
				reg-names = "dsi_ctrl";

				interrupt-parent = <&mdss>;
				interrupts = <5 IRQ_TYPE_LEVEL_HIGH>;

				assigned-clocks =
					<&gcc GCC_MDSS_BYTE1_CLK_SRC>,
					<&gcc GCC_MDSS_PCLK1_CLK_SRC>;
				assigned-clock-parents = <&dsi1_phy 0>,
							 <&dsi1_phy 1>;

				clocks = <&gcc GCC_MDSS_MDP_CLK>,
					 <&gcc GCC_MDSS_AHB_CLK>,
					 <&gcc GCC_MDSS_AXI_CLK>,
					 <&gcc GCC_MDSS_BYTE1_CLK>,
					 <&gcc GCC_MDSS_PCLK1_CLK>,
					 <&gcc GCC_MDSS_ESC1_CLK>;
				clock-names = "mdp_core",
					      "iface",
					      "bus",
					      "byte",
					      "pixel",
					      "core";
				phys = <&dsi1_phy>;
				phy-names = "dsi-phy";

				//operating-points-v2 = <&dsi1_opp_table>;
				power-domains = <&rpmpd MSM8976_VDDCX>;

				status = "disabled";

				ports {
					#address-cells = <1>;
					#size-cells = <0>;

					port@0 {
						reg = <0>;
						dsi1_in: endpoint {
							remote-endpoint = <&mdp5_intf2_out>;
						};
					};

					port@1 {
						reg = <1>;
						dsi1_out: endpoint {
						};
					};
				};
			};

			dsi0_phy: dsi-phy@1a94a00 {
				compatible = "qcom,dsi-phy-28nm-hpm-fam-b";
				reg = <0x01a94a00 0xd4>,
				      <0x01a94400 0x280>,
				      <0x01a94b80 0x30>;
				reg-names = "dsi_pll",
					    "dsi_phy",
					    "dsi_phy_regulator";

				#clock-cells = <1>;
				#phy-cells = <0>;

				clocks = <&gcc GCC_MDSS_AHB_CLK>, <&xo_board>;
					
				clock-names = "iface", "ref";
			};

			dsi1_phy: dsi-phy@1a96a00 {
				compatible = "qcom,dsi-phy-28nm-hpm-fam-b";
				reg = <0x01a96a00 0xd4>,
				      <0x01a96400 0x280>,
				      <0x01a96b80 0x30>;
				reg-names = "dsi_pll",
					    "dsi_phy",
					    "dsi_phy_regulator";

				#clock-cells = <1>;
				#phy-cells = <0>;

				clocks = <&gcc GCC_MDSS_AHB_CLK>, <&xo_board>;
				clock-names = "iface", "ref";

				status="disabled";
			};
		};

		adreno_gpu: gpu@1c00000 {
			compatible = "qcom,adreno-510.0", "qcom,adreno";
			#stream-id-cells = <16>;
			status = "okay";
			reg = <0x01c00000 0x40000>;
			reg-names = "kgsl_3d0_reg_memory";

			interrupts = <GIC_SPI 33 IRQ_TYPE_LEVEL_HIGH>;
			interrupt-names = "kgsl_3d0_irq";
			
			clock-names =
			    "core",
			    "iface",
			    "mem",
			    "rbbmtimer",
			    "gtcu",
			    "gtbu",
			    "alwayson";

			clocks =
			    <&gcc GCC_GFX3D_OXILI_CLK>,
			    <&gcc GCC_GFX3D_OXILI_AHB_CLK>,
			    <&gcc GCC_GFX3D_BIMC_CLK>,
			    <&gcc GCC_GFX3D_OXILI_TIMER_CLK>,
			    <&gcc GCC_GFX3D_GTCU_AHB_CLK>,
			    <&gcc GCC_GFX3D_TBU1_CLK>,
			    <&gcc GCC_GFX3D_OXILI_AON_CLK>;

			power-domains = <&gcc OXILI_CX_GDSC>,
			<&gcc OXILI_GX_GDSC>,
			<&rpmpd MSM8976_VDDCX>;
			power-domain-names = "cx", "gx", "pstate";
			
			interconnects = <&bimc MAS_OXILI &bimc SLV_EBI>,
					<&bimc MAS_APPS_PROC &pcnoc SLV_GPU_CFG>; // Downstream doesn't handlde this,
										  // so values are made up.
			
			iommus = <&gpu_iommu 0>;

			operating-points-v2 = <&gpu_opp_table>;
			
			gpu_opp_table: opp-table {
				compatible  ="operating-points-v2";
				GPU_OPP(200000, 2227200, rpmpd_opp_low_svs, 0xff);
				GPU_OPP(300000, 3072000, rpmpd_opp_svs, 0xff);
				GPU_OPP(400000, 4300800, rpmpd_opp_nom, 0xff);
				GPU_OPP(480000, 5990400 ,rpmpd_opp_nom_plus, 0xff);
				GPU_OPP(550000, 7449600, rpmpd_opp_turbo, 0xff);
				//GPU_OPP(600000, 7449600, rpmpd_opp_turbo, 0xff);
			};
		};

		tsens0: thermal-sensor@4a8000 {
			compatible = "qcom,msm8976-tsens";
			reg = <0x4a9000 0x1000>, /* TM */
			      <0x4a8000 0x1000>; /* SROT */
			nvmem-cells = <&tsens_caldata>;
			interrupts = <GIC_SPI 184 IRQ_TYPE_LEVEL_HIGH>;
			interrupt-names = "uplow";
			nvmem-cell-names = "calib";
			#qcom,sensors = <11>;
			#thermal-sensor-cells = <1>;
		};
		
		spmi_bus: spmi@200f000 {
			compatible = "qcom,spmi-pmic-arb";
			reg = <0x200f000 0x1000>,
				<0x2400000 0x800000>,
				<0x2c00000 0x800000>,
				<0x3800000 0x200000>,
				<0x200a000 0x2100>;
			reg-names = "core", "chnls", "obsrvr", "intr", "cnfg";
			interrupts = <GIC_SPI 190 IRQ_TYPE_LEVEL_HIGH>;
			interrupt-names = "periph_irq";
			qcom,channel = <0>;
			qcom,ee = <0>;
			qcom,max-peripherals = <256>;
			qcom,max-periph-interrupts = <256>;
			#address-cells = <2>;
			#size-cells = <0>;
			interrupt-controller;
			#interrupt-cells = <4>;
		};
		
		blsp_dma: dma@7884000 {
			compatible = "qcom,bam-v1.7.0";
			reg = <0x07884000 0x1f000>;
			interrupts = <GIC_SPI 238 IRQ_TYPE_LEVEL_HIGH>;
			clocks = <&gcc GCC_BLSP1_AHB_CLK>;
			clock-names = "bam_clk";
			#dma-cells = <1>;
			qcom,ee = <0>;
			status = "disabled";
		};

		blsp2_dma: dma@7ac4000 {
			compatible = "qcom,bam-v1.7.0";
			reg = <0x7ac4000 0x1f000>;
			interrupts = <GIC_SPI 239 IRQ_TYPE_LEVEL_HIGH>;
			clocks = <&gcc GCC_BLSP2_AHB_CLK>;
			clock-names = "bam_clk";
			#dma-cells = <1>;
			qcom,ee = <0>;
			status = "disabled";
		};

		sdhc_1: sdhci@7824000 {
			compatible = "qcom,sdhci-msm-v4";
			reg = <0x07824900 0x500>, <0x07824000 0x800>;
			reg-names = "hc_mem", "core_mem";

			interrupts = <GIC_SPI 123 IRQ_TYPE_LEVEL_HIGH>,
				     <GIC_SPI 138 IRQ_TYPE_LEVEL_HIGH>;
			interrupt-names = "hc_irq", "pwr_irq";
			power-domains = <&rpmpd MSM8976_VDDCX>;
			clocks = <&gcc GCC_SDCC1_APPS_CLK>,
				 <&gcc GCC_SDCC1_AHB_CLK>,
				 <&xo_board>;
			clock-names = "core", "iface", "xo";
			operating-points-v2 = <&sdhc1_opp_table>;
			interconnects = <&pcnoc MAS_SDCC_1 &bimc SLV_EBI>,
					<&bimc MAS_APPS_PROC &pcnoc SLV_SDCC_1>;

			mmc-hs200-1_8v;
			mmc-hs400-1_8v;
			mmc-ddr-1_8v;
			bus-width = <8>;
			non-removable;
			status = "disabled";
			
			sdhc1_opp_table: sdhc1-opp-table {
				compatible = "operating-points-v2";

				opp-100000000 {
					opp-hz = /bits/ 64 <100000000>;
					opp-peak-kBps = <400000>, <400000>;
					opp-avg-kBps = <130718>, <65360>;
					required-opps = <&rpmpd_opp_svs>;
				};

				opp-186400000 {
					opp-hz = /bits/ 64 <186400000>;
					opp-peak-kBps = <800000>, <600000>;
					opp-avg-kBps = <261438>, <130718>;
					required-opps = <&rpmpd_opp_nom>;
				};


				opp-372800000 {
					opp-hz = /bits/ 64 <372800000>;
					opp-peak-kBps = <800000>, <800000>;
					opp-avg-kBps = <261438>, <300000>;
					required-opps = <&rpmpd_opp_nom>;
				};
			};
		};

		sdhc_2: sdhci@7864000 {
			compatible = "qcom,sdhci-msm-v4";
			reg = <0x07864900 0x11c>, <0x07864000 0x800>;
			reg-names = "hc_mem", "core_mem";

			interrupts = <GIC_SPI 125 IRQ_TYPE_LEVEL_HIGH>,
				     <GIC_SPI 221 IRQ_TYPE_LEVEL_HIGH>;
			interrupt-names = "hc_irq", "pwr_irq";

			clocks = <&gcc GCC_SDCC2_APPS_CLK>,
				 <&gcc GCC_SDCC2_AHB_CLK>,
				 <&xo_board>;
			clock-names = "core", "iface", "xo";
			power-domains = <&rpmpd MSM8976_VDDCX>;
			operating-points-v2 = <&sdhc2_opp_table>;

			bus-width = <4>;
			status = "disabled";
			
			sdhc2_opp_table: sdhc2-opp-table {
				compatible = "operating-points-v2";

				opp-50000000 {
					opp-hz = /bits/ 64 <50000000>;
					required-opps = <&rpmpd_opp_svs>;
				};

				opp-200000000 {
					opp-hz = /bits/ 64 <200000000>;
					required-opps = <&rpmpd_opp_nom>;
				};

			};
		};

		sdhc_3: sdhci@7a24000 {
			compatible = "qcom,sdhci-msm-v4";
			reg = <0x07a24900 0x11c>, <0x07a24000 0x800>;
			reg-names = "hc_mem", "core_mem";

			interrupts = <GIC_SPI 295 IRQ_TYPE_LEVEL_HIGH>,
				     <GIC_SPI 297 IRQ_TYPE_LEVEL_HIGH>;
			interrupt-names = "hc_irq", "pwr_irq";

			clocks = <&gcc GCC_SDCC3_APPS_CLK>,
				 <&gcc GCC_SDCC3_AHB_CLK>,
				 <&xo_board>;
			clock-names = "core", "iface", "xo";

			bus-width = <4>;
			status = "disabled";
		};

		blsp1_uart1: serial@78af000 {
			compatible = "qcom,msm-uartdm-v1.4", "qcom,msm-uartdm";
			reg = <0x078af000 0x200>;
			interrupts = <GIC_SPI 107 IRQ_TYPE_LEVEL_HIGH>;
			clocks = <&gcc GCC_BLSP1_UART1_APPS_CLK>, <&gcc GCC_BLSP1_AHB_CLK>;
			clock-names = "core", "iface";
			dmas = <&blsp_dma 1>, <&blsp_dma 0>;
			dma-names = "rx", "tx";
			pinctrl-names = "default";
			pinctrl-0 = <&blsp1_uart1_default>;
			status = "disabled";
		};

		blsp1_uart2: serial@78b0000 {
			compatible = "qcom,msm-uartdm-v1.4", "qcom,msm-uartdm";
			reg = <0x078b0000 0x200>;
			interrupts = <GIC_SPI 108 IRQ_TYPE_LEVEL_HIGH>;
			clocks = <&gcc GCC_BLSP1_UART2_APPS_CLK>, <&gcc GCC_BLSP1_AHB_CLK>;
			clock-names = "core", "iface";
			dmas = <&blsp_dma 3>, <&blsp_dma 2>;
			dma-names = "rx", "tx";
			pinctrl-names = "default";
			pinctrl-0 = <&blsp1_uart2_default>;
			status = "disabled";
		};

		blsp2_uart2: serial@7af0000 {
			compatible = "qcom,msm-uartdm-v1.4", "qcom,msm-uartdm";
			reg = <0x07af0000 0x200>;
			interrupts = <GIC_SPI 307 IRQ_TYPE_LEVEL_HIGH>;
			clocks = <&gcc GCC_BLSP2_UART2_APPS_CLK>,
				 <&gcc GCC_BLSP2_AHB_CLK>;
			clock-names = "core", "iface";
			dmas = <&blsp2_dma 1>, <&blsp2_dma 0>;
			dma-names = "rx", "tx";
			pinctrl-names = "default";
			pinctrl-0 = <&blsp2_uart2_default>;
			status = "disabled";
		};

		blsp1_spi0: spi@78b5000 {
			compatible = "qcom,spi-qup-v2.2.1";
			reg = <0x078b5000 0x500>;
			interrupts = <GIC_SPI 95 IRQ_TYPE_LEVEL_HIGH>;
			clocks = <&gcc GCC_BLSP1_QUP1_SPI_APPS_CLK>,
				 <&gcc GCC_BLSP1_AHB_CLK>;
			clock-names = "core", "iface";
			dmas = <&blsp_dma 5>, <&blsp_dma 4>;
			dma-names = "rx", "tx";
			pinctrl-names = "default";
			pinctrl-0 = <&spi0_default>;
			#address-cells = <1>;
			#size-cells = <0>;
			status = "disabled";
		};

		blsp_i2c2: i2c@78b6000 {
			compatible = "qcom,i2c-qup-v2.2.1";
			reg = <0x078b6000 0x500>;
			interrupts = <GIC_SPI 96 IRQ_TYPE_LEVEL_HIGH>;
			clocks = <&gcc GCC_BLSP1_AHB_CLK>,
				 <&gcc GCC_BLSP1_QUP2_I2C_APPS_CLK>;
			clock-names = "iface", "core";
			pinctrl-names = "default";
			pinctrl-0 = <&i2c2_default>;
			#address-cells = <1>;
			#size-cells = <0>;
			status = "disabled";
		};

		blsp_i2c4: i2c@78b8000 {
			compatible = "qcom,i2c-qup-v2.2.1";
			reg = <0x078b8000 0x500>;
			interrupts = <GIC_SPI 98 IRQ_TYPE_LEVEL_HIGH>;
			clocks = <&gcc GCC_BLSP1_AHB_CLK>,
				 <&gcc GCC_BLSP1_QUP4_I2C_APPS_CLK>;
			clock-names = "iface", "core";
			pinctrl-names = "default";
			pinctrl-0 = <&i2c4_default>;
			#address-cells = <1>;
			#size-cells = <0>;
			status = "disabled";
		};
		
		blsp_i2c6: i2c@7af6000 {
			compatible = "qcom,i2c-qup-v2.2.1";
			reg = <0x07af6000 0x600>;
			interrupts = <GIC_SPI 300 IRQ_TYPE_LEVEL_HIGH>;
			clocks = <&gcc GCC_BLSP2_AHB_CLK>,
				 <&gcc GCC_BLSP2_QUP2_I2C_APPS_CLK>;
			clock-names = "iface", "core";
			pinctrl-names = "default";
			pinctrl-0 = <&i2c6_default>;
			#address-cells = <1>;
			#size-cells = <0>;
			status = "disabled";
		};

		blsp_i2c8: i2c@7af8000 {
			compatible = "qcom,i2c-qup-v2.2.1";
			reg = <0x07af8000 0x600>;
			interrupts = <GIC_SPI 302 IRQ_TYPE_LEVEL_HIGH>;
			clocks = <&gcc GCC_BLSP2_AHB_CLK>,
				 <&gcc GCC_BLSP2_QUP4_I2C_APPS_CLK>;
			clock-names = "iface", "core";
			pinctrl-names = "default";
			pinctrl-0 = <&i2c8_default>;
			#address-cells = <1>;
			#size-cells = <0>;
			status = "disabled";
		};

		usb: usb@78db000 {
			compatible = "qcom,ci-hdrc";
			reg = <0x78db000 0x200>,
			      <0x78db200 0x200>;
			interrupts = <GIC_SPI 134 IRQ_TYPE_LEVEL_HIGH>,
				     <GIC_SPI 140 IRQ_TYPE_LEVEL_HIGH>;
			clocks = <&gcc GCC_USB_HS_AHB_CLK>,
				 <&gcc GCC_USB_HS_SYSTEM_CLK>;
			clock-names = "iface", "core";
			assigned-clocks = <&gcc GCC_USB_HS_SYSTEM_CLK>;
			assigned-clock-rates = <133333333>;
			resets = <&gcc RST_USB_HS_BCR>;
			reset-names = "core";
			phy_type = "ulpi";
			dr_mode = "peripheral";
			ahb-burst-config = <0>;
			phy-names = "usb-phy";
			phys = <&usb_hs_phy>;
			status = "disabled";
			#reset-cells = <1>;
	
		};
		modem: remoteproc@4080000 {
			compatible = "qcom,msm8953-mss-pil";
			reg = <0x4080000 0x100>,
			      <0x4020000 0x040>;
			
			reg-names = "qdsp6", "rmb";

			interrupts-extended = <&intc 0 24 1>,
					      <&modem_smp2p_in 0 0>,
					      <&modem_smp2p_in 1 0>,
					      <&modem_smp2p_in 2 0>,
					      <&modem_smp2p_in 3 0>;
			interrupt-names = "wdog", "fatal", "ready",
					  "handover", "stop-ack";

			clocks = <&gcc GCC_MSS_CFG_AHB_CLK>,
				 <&gcc GCC_MSS_Q6_BIMC_AXI_CLK>,
				 <&gcc GCC_BOOT_ROM_AHB_CLK>,
				 <&xo_board>;
			clock-names = "iface", "bus", "mem", "xo";

			power-domains = <&rpmpd MSM8976_VDDCX>, <&rpmpd MSM8976_VDDMX>;
			power-domain-names = "cx", "mx";

			qcom,smem-states = <&modem_smp2p_out 0>;
			qcom,smem-state-names = "stop";

			resets = <&gcc RST_MSS_BCR>;
			reset-names = "mss_restart";

			qcom,halt-regs = <&tcsr 0x18000 0x19000 0x1a000>;

			

			mba {
				memory-region = <&mba_mem>;
			};

			mpss {
				memory-region = <&mpss_mem>;
			};

			smd-edge {
				interrupts = <GIC_SPI 25 IRQ_TYPE_EDGE_RISING>;

				qcom,smd-edge = <0>;
				qcom,ipc = <&apcs 8 12>;
				qcom,remote-pid = <1>;

				label = "modem";
			};
		};

		pronto: remoteproc@a21b000 {
			compatible = "qcom,pronto-v3-pil", "qcom,pronto";
			reg = <0xa204000 0x2000>,
			      <0xa202000 0x1000>,
			      <0xa21b000 0x3000>;
			reg-names = "ccu", "dxe", "pmu";
			memory-region = <&wcnss_fw_mem>;

			interrupts-extended = <&intc 0 149 IRQ_TYPE_EDGE_RISING>,
					      <&wcnss_smp2p_in 0 IRQ_TYPE_EDGE_RISING>,
					      <&wcnss_smp2p_in 1 IRQ_TYPE_EDGE_RISING>,
					      <&wcnss_smp2p_in 2 IRQ_TYPE_EDGE_RISING>,
					      <&wcnss_smp2p_in 3 IRQ_TYPE_EDGE_RISING>;
			interrupt-names = "wdog", "fatal", "ready", "handover", "stop-ack";

			power-domains = <&rpmpd MSM8976_VDDCX>, <&rpmpd MSM8976_VDDMX>;
			power-domain-names = "cx", "mx";

			qcom,smem-states = <&wcnss_smp2p_out 0>;
			qcom,smem-state-names = "stop";

			pinctrl-names = "default", "sleep";
			pinctrl-0 = <&wcnss_default>;
			pinctrl-1 = <&wcnss_sleep>;
			status = "ok";
			
			iris: iris {
				compatible = "qcom,wcn3680";
			
				clocks = <&rpmcc RPM_SMD_RF_CLK2>;
				clock-names = "xo";
			};

			smd-edge {
				interrupts = <GIC_SPI 142 IRQ_TYPE_EDGE_RISING>;

				qcom,ipc = <&apcs 8 17>;
				qcom,smd-edge = <6>;
				qcom,remote-pid = <4>;

				label = "pronto";

				wcnss {
					compatible = "qcom,wcnss";
					qcom,smd-channels = "WCNSS_CTRL";

					qcom,mmio = <&pronto>;

					bt {
						compatible = "qcom,wcnss-bt";
					};

					wifi {
						compatible = "qcom,wcnss-wlan";

						interrupts = <GIC_SPI 145 IRQ_TYPE_LEVEL_HIGH>,
							     <GIC_SPI 146 IRQ_TYPE_LEVEL_HIGH>;
						interrupt-names = "tx", "rx";

						qcom,smem-states = <&apps_smsm 10>, <&apps_smsm 9>;
						qcom,smem-state-names = "tx-enable", "tx-rings-empty";
					};
				};
			};
		};

		sound_card: sound-card@c051000 {
			compatible = "qcom,msm8976-qdsp6-sndcard";
			reg = <0xc051000 0x4>,
			      <0xc051004 0x4>,
			      <0xc055000 0x4>,
			      <0xc052000 0x4>;
			reg-names = "mic-iomux",
				    "spkr-iomux",
				    "pri-iomux",
				    "quin-iomux";

			audio-routing =
				"AMIC1", "MIC BIAS External1",
				"AMIC2", "MIC BIAS External2",
				"AMIC3", "MIC BIAS External1",
				"MM_DL1", "MultiMedia1 Playback",
				"MM_DL3", "MultiMedia3 Playback",
				"MM_DL4", "MultiMedia4 Playback",
				"MultiMedia2 Capture", "MM_UL2";

			status = "disabled";
			
			mm1-dai-link {
				link-name = "MultiMedia1";
				cpu {
					sound-dai = <&q6asmdai MSM_FRONTEND_DAI_MULTIMEDIA1>;
				};
			};

			mm2-dai-link {
				link-name = "MultiMedia2";
				cpu {
					sound-dai = <&q6asmdai MSM_FRONTEND_DAI_MULTIMEDIA2>;
				};
			};

			mm3-dai-link {
				link-name = "MultiMedia3";
				cpu {
					sound-dai = <&q6asmdai MSM_FRONTEND_DAI_MULTIMEDIA3>;
				};
			};

			mm4-dai-link {
				link-name = "MultiMedia4";
				cpu {
					sound-dai = <&q6asmdai MSM_FRONTEND_DAI_MULTIMEDIA4>;
				};
			};

			cs-voice-dai-link {
				link-name = "CS-Voice";
				cpu {
					sound-dai = <&q6voicedai CS_VOICE>;
				};
			};
			
			sound_dai_primary: primary-mi2s-dai-link {
				link-name = "Primary MI2S";
				cpu {
					sound-dai = <&q6afedai PRIMARY_MI2S_RX>;
				};

				platform {
					sound-dai = <&q6routing>;
				};

				codec {
					sound-dai = <&lpass_codec 0>, <&wcd_codec 0>;
				};
			};
			
			
			sound_dai_secondary: dai-link-secondary {
				link-name = "Secondary MI2S";
				status = "disabled"; /* Needs extra codec configuration */
				cpu {
					sound-dai = <&q6afedai SECONDARY_MI2S_RX>;
				};
				platform {
					sound-dai = <&q6routing>;
				};
			};

		sound_dai_tertiary: dai-link-tertiary {
				
				link-name = "Tertiary MI2S";
				cpu {
					sound-dai = <&q6afedai TERTIARY_MI2S_TX>;
				};

				platform {
					sound-dai = <&q6routing>;
				};

				codec {
					sound-dai = <&lpass_codec 1>, <&wcd_codec 1>;
				};
			};

			
		};
		
		lpass_codec: codec {
			compatible = "qcom,msm8916-wcd-digital-codec";
			reg = <0x0c0f0000 0x400>;
			#sound-dai-cells = <1>;
		};

		lpass: remoteproc@c200000 {
			compatible = "qcom,msm8953-adsp-pil";
			reg = <0xc200000 0x100>;
				
			interrupts-extended = <&intc 0 293 IRQ_TYPE_EDGE_RISING>,
					      <&smp2p_adsp_in 0 IRQ_TYPE_EDGE_RISING>,
					      <&smp2p_adsp_in 1 IRQ_TYPE_EDGE_RISING>,
					      <&smp2p_adsp_in 2 IRQ_TYPE_EDGE_RISING>,
					      <&smp2p_adsp_in 3 IRQ_TYPE_EDGE_RISING>;
			interrupt-names = "wdog", "fatal", "ready",
					  "handover", "stop-ack";
			clocks = <&xo_board>;
			clock-names = "xo";
			
			power-domains = <&rpmpd MSM8976_VDDCX>;
			power-domain-names = "cx";

			memory-region = <&lpass_mem>;

			qcom,smem-states = <&smp2p_adsp_out 0>;
			qcom,smem-state-names = "stop";

			smd-edge {
				interrupts = <GIC_SPI 289 IRQ_TYPE_EDGE_RISING>;

				label = "lpass";
				mboxes = <&apcs 8>;
				qcom,smd-edge = <1>;
				qcom,remote-pid = <2>;
				#address-cells = <1>;
				#size-cells = <0>;

				apr {
					compatible = "qcom,apr-v2";
					qcom,smd-channels = "apr_audio_svc";
					qcom,apr-domain = <APR_DOMAIN_ADSP>;
					#address-cells = <1>;
					#size-cells = <0>;

					q6core {
						reg = <APR_SVC_ADSP_CORE>;
						compatible = "qcom,q6core";
					};

					q6afe: q6afe {
						compatible = "qcom,q6afe";
						reg = <APR_SVC_AFE>;
						q6afedai: dais {
							compatible = "qcom,q6afe-dais";
							#address-cells = <1>;
							#size-cells = <0>;
							#sound-dai-cells = <1>;
							
							dai@16 {
								reg = <PRIMARY_MI2S_RX>;
								qcom,sd-lines = <0 1>;
							};
							
							dai@21 {
								reg = <TERTIARY_MI2S_TX>;
								qcom,sd-lines = <0 1>;
							};
						};
						
					};

					q6asm: q6asm {
						compatible = "qcom,q6asm";
						reg = <APR_SVC_ASM>;
						q6asmdai: dais {
							compatible = "qcom,q6asm-dais";
							#address-cells = <1>;
							#size-cells = <0>;
							#sound-dai-cells = <1>;
							dai@0 {
								reg = <MSM_FRONTEND_DAI_MULTIMEDIA1>;
							};
							dai@1 {
								reg = <MSM_FRONTEND_DAI_MULTIMEDIA2>;
							};

							dai@2 {
								reg = <MSM_FRONTEND_DAI_MULTIMEDIA3>;
							};

							dai@3 {
								reg = <MSM_FRONTEND_DAI_MULTIMEDIA4>;
								is-compress-dai;
							};
						};
					};

					q6adm: q6adm {
						compatible = "qcom,q6adm";
						reg = <APR_SVC_ADM>;
						q6routing: routing {
							compatible = "qcom,q6adm-routing";
							#sound-dai-cells = <0>;
						};
					};

					q6mvm: apr-service@9 {
						compatible = "qcom,q6mvm";
						reg = <APR_SVC_ADSP_MVM>;

						q6voicedai: dais {
							compatible = "qcom,q6voice-dais";
							#sound-dai-cells = <0>;
						};
					};

					q6cvs: apr-service@a {
						compatible = "qcom,q6cvs";
						reg = <APR_SVC_ADSP_CVS>;
					};

					q6cvp: apr-service@b {
						compatible = "qcom,q6cvp";
						reg = <APR_SVC_ADSP_CVP>;
					};
				};
			};
		};
	smem {
		compatible = "qcom,smem";

		memory-region = <&smem_mem>;
		qcom,rpm-msg-ram = <&rpm_msg_ram>;

		hwlocks = <&tcsr_mutex 3>;
	};

	smd {
		compatible = "qcom,smd";

		rpm {
			interrupts = <GIC_SPI 168 IRQ_TYPE_EDGE_RISING>;
			qcom,ipc = <&apcs 8 0>;
			qcom,smd-edge = <15>;

			rpm_requests: rpm_requests {
				compatible = "qcom,rpm-msm8976";
				qcom,smd-channels = "rpm_requests";
				qcom,smd-force-open;


				rpmcc: rpmcc {
					compatible = "qcom,rpmcc-msm8976";
					#clock-cells = <1>;
				};

				rpmpd: power-controller {
					compatible = "qcom,msm8976-rpmpd";
					#power-domain-cells = <1>;
					operating-points-v2 = <&rpmpd_opp_table>;
					clocks = <&xo_board>;
					clock-names = "ref";
					
						rpmpd_opp_table: opp-table {
							compatible = "operating-points-v2";

							rpmpd_opp_ret: opp1 {
							opp-level = <RPM_SMD_LEVEL_RETENTION>;
							};

							rpmpd_opp_ret_plus: opp2 {
							opp-level = <RPM_SMD_LEVEL_RETENTION_PLUS>;
							};

							rpmpd_opp_min_svs: opp3 {
							opp-level = <RPM_SMD_LEVEL_MIN_SVS>;
							};

							rpmpd_opp_low_svs: opp4 {
							opp-level = <RPM_SMD_LEVEL_LOW_SVS>;
							};

							rpmpd_opp_svs: opp5 {
							opp-level = <RPM_SMD_LEVEL_SVS>;
							};

							rpmpd_opp_svs_plus: opp6 {
							opp-level = <RPM_SMD_LEVEL_SVS_PLUS>;
							};

							rpmpd_opp_nom: opp7 {
							opp-level = <RPM_SMD_LEVEL_NOM>;
							};

							rpmpd_opp_nom_plus: opp8 {
							opp-level = <RPM_SMD_LEVEL_NOM_PLUS>;
							};

							rpmpd_opp_turbo: opp9 {
							opp-level = <RPM_SMD_LEVEL_TURBO>;
							};

							rpmpd_opp_turbo_no_cpr: opp10 {
							opp-level = <RPM_SMD_LEVEL_TURBO_NO_CPR>;
							};

							rpmpd_opp_turbo_high: opp111 {
							opp-level = <RPM_SMD_LEVEL_TURBO_HIGH>;
							};
						};
					};
			};
		};
	};


	modem-smp2p {
		compatible = "qcom,smp2p";
		qcom,smem = <435>, <428>;

		interrupts = <GIC_SPI 27 IRQ_TYPE_EDGE_RISING>;

		qcom,ipc = <&apcs 8 14>;

		qcom,local-pid = <0>;
		qcom,remote-pid = <1>;

		modem_smp2p_out: master-kernel {
			qcom,entry-name = "master-kernel";

			#qcom,smem-state-cells = <1>;
		};

		modem_smp2p_in: slave-kernel {
			qcom,entry-name = "slave-kernel";

			interrupt-controller;
			#interrupt-cells = <2>;
		};
	};

	adsp-smp2p {
		compatible = "qcom,smp2p";
		qcom,smem = <443>, <429>;

		interrupts = <GIC_SPI 291 IRQ_TYPE_EDGE_RISING>;

		mboxes = <&apcs 10>;

		qcom,local-pid = <0>;
		qcom,remote-pid = <2>;

		smp2p_adsp_out: master-kernel {
			qcom,entry-name = "master-kernel";
			#qcom,smem-state-cells = <1>;
		};

		smp2p_adsp_in: slave-kernel {
			qcom,entry-name = "slave-kernel";

			interrupt-controller;
			#interrupt-cells = <2>;
		};
	};

	wcnss-smp2p {
		compatible = "qcom,smp2p";
		qcom,smem = <451>, <431>;

		interrupts = <GIC_SPI 143 IRQ_TYPE_EDGE_RISING>;

		qcom,ipc = <&apcs 8 18>;

		qcom,local-pid = <0>;
		qcom,remote-pid = <4>;

		wcnss_smp2p_out: master-kernel {
			qcom,entry-name = "master-kernel";

			#qcom,smem-state-cells = <1>;
		};

		wcnss_smp2p_in: slave-kernel {
			qcom,entry-name = "slave-kernel";

			interrupt-controller;
			#interrupt-cells = <2>;
		};
	};

	smsm {
		compatible = "qcom,smsm";

		#address-cells = <1>;
		#size-cells = <0>;

		qcom,ipc-1 = <&apcs 8 13>;
		qcom,ipc-3 = <&apcs 8 19>;

		apps_smsm: apps@0 {
			reg = <0>;
			#qcom,smem-state-cells = <1>;
		};

		hexagon_smsm: hexagon@1 {
			reg = <1>;
			interrupts = <GIC_SPI 290 IRQ_TYPE_EDGE_RISING>;

			interrupt-controller;
			#interrupt-cells = <2>;
		};

		wcnss_smsm: wcnss@6 {
			reg = <6>;
			interrupts = <GIC_SPI 144 IRQ_TYPE_EDGE_RISING>;

			interrupt-controller;
			#interrupt-cells = <2>;
		};
	};


	thermal_zones: thermal-zones {
		aoss0-thermal {
			polling-delay-passive = <250>;
			polling-delay = <1000>;

			thermal-sensors = <&tsens0 0>;
			trips {
				aoss0_alert: trip-point@0 {
					temperature = <105000>;
					hysteresis = <2000>;
					type = "hot";
				};
			};
		};

		mdm-core-thermal {
			polling-delay-passive = <250>;
			polling-delay = <1000>;

			thermal-sensors = <&tsens0 1>;
			trips {
				modem_alert: trip-point@0 {
					temperature = <95000>;
					hysteresis = <2000>;
					type = "hot";
				};
			};
		};

		qdsp-thermal {
			polling-delay-passive = <250>;
			polling-delay = <1000>;

			thermal-sensors = <&tsens0 2>;
			trips {
				qdsp_alert: trip-point@0 {
					temperature = <95000>;
					hysteresis = <2000>;
					type = "hot";
				};
			};
		};

		cam-isp-thermal {
			polling-delay-passive = <250>;
			polling-delay = <1000>;

			thermal-sensors = <&tsens0 3>;
			trips {
				cam_isp_alert: trip-point@0 {
					temperature = <95000>;
					hysteresis = <2000>;
					type = "hot";
				};
			};
		};

		apc1-cpu0-thermal {
			polling-delay-passive = <250>;
			polling-delay = <1000>;
			thermal-sensors = <&tsens0 4>;

			trips {
				cpu4_alert0: trip-point@0 {
					temperature = <95000>;
					hysteresis = <2000>;
					type = "hot";
				};
				cpu4_alert1: trip-point@1 {
					temperature = <105000>;
					hysteresis = <2000>;
					type = "passive";
				};
				cpu4_crit: trip-point@2 {
					temperature = <120000>;
					hysteresis = <2000>;
					type = "critical";
				};
			};
		};

		apc1-cpu1-thermal {
			polling-delay-passive = <250>;
			polling-delay = <1000>;
			thermal-sensors = <&tsens0 5>;

			trips {
				cpu5_alert0: trip-point@0 {
					temperature = <95000>;
					hysteresis = <2000>;
					type = "hot";
				};
				cpu5_alert1: trip-point@1 {
					temperature = <105000>;
					hysteresis = <2000>;
					type = "passive";
				};
				cpu5_crit: trip-point@2 {
					temperature = <120000>;
					hysteresis = <2000>;
					type = "critical";
				};
			};
		};

		apc1-cpu2-thermal {
			polling-delay-passive = <250>;
			polling-delay = <1000>;
			thermal-sensors = <&tsens0 6>;

			trips {
				cpu6_alert0: trip-point@0 {
					temperature = <95000>;
					hysteresis = <2000>;
					type = "hot";
				};
				cpu6_alert1: trip-point@1 {
					temperature = <105000>;
					hysteresis = <2000>;
					type = "passive";
				};
				cpu6_crit: trip-point@2 {
					temperature = <120000>;
					hysteresis = <2000>;
					type = "critical";
				};
			};
		};

		apc1-cpu3-thermal {
			polling-delay-passive = <250>;
			polling-delay = <1000>;
			thermal-sensors = <&tsens0 7>;

			trips {
				cpu7_alert0: trip-point@0 {
					temperature = <95000>;
					hysteresis = <2000>;
					type = "hot";
				};
				cpu7_alert1: trip-point@1 {
					temperature = <105000>;
					hysteresis = <2000>;
					type = "passive";
				};
				cpu7_crit: trip-point@2 {
					temperature = <120000>;
					hysteresis = <2000>;
					type = "critical";
				};
			};
		};

		apc1-l2-thermal {
			polling-delay-passive = <250>;
			polling-delay = <1000>;
			thermal-sensors = <&tsens0 8>;

			trips {
				l2_alert0: trip-point@0 {
					temperature = <95000>;
					hysteresis = <2000>;
					type = "hot";
				};
				l2_alert1: trip-point@1 {
					temperature = <105000>;
					hysteresis = <2000>;
					type = "passive";
				};
				l2_crit: trip-point@2 {
					temperature = <120000>;
					hysteresis = <2000>;
					type = "critical";
				};
			};
		};

		apc0-cpu0-thermal {
			polling-delay-passive = <250>;
			polling-delay = <1000>;
			thermal-sensors = <&tsens0 9>;

			trips {
				cpu0_alert0: trip-point@0 {
					temperature = <95000>;
					hysteresis = <2000>;
					type = "hot";
				};
				cpu0_alert1: trip-point@1 {
					temperature = <105000>;
					hysteresis = <2000>;
					type = "passive";
				};
				cpu0_crit: trip-point@2 {
					temperature = <120000>;
					hysteresis = <2000>;
					type = "critical";
				};
			};
		};
	};
};
};
